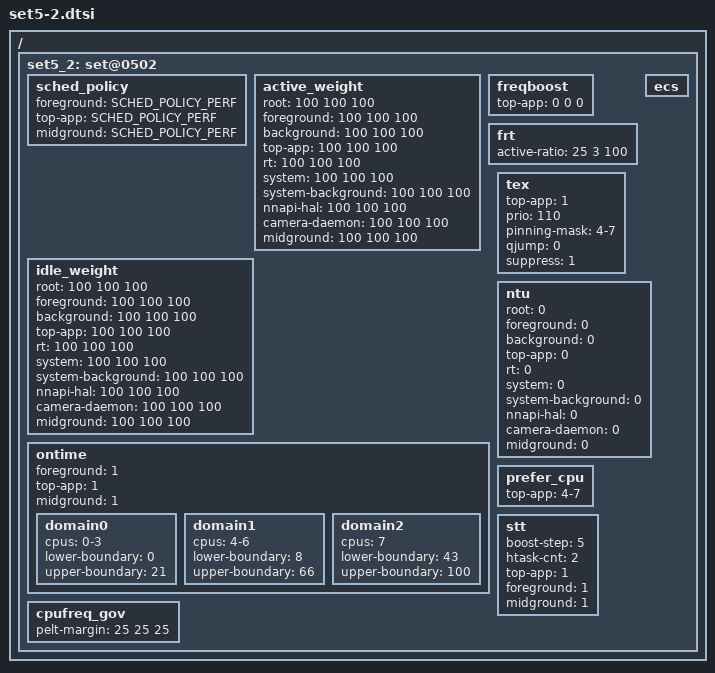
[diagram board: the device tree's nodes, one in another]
/ {
	/* camera mode - app boost */
	set5_2: set@0502 {
		/* schedudling policy */
		sched_policy {
			foreground 		= <SCHED_POLICY_PERF>;
			top-app			= <SCHED_POLICY_PERF>;
			midground = <SCHED_POLICY_PERF>;
		};

		/* weight (%) applied to active cpu's efficiency */
		active_weight {			/* LIT MED BIG */
			root            	= <100 100 100>;
			foreground      	= <100 100 100>;
			background      	= <100 100 100>;
			top-app         	= <100 100 100>;
			rt			= <100 100 100>;
			system			= <100 100 100>;
			system-background	= <100 100 100>;
			nnapi-hal		= < 100 100 100>;
			camera-daemon		= <100 100 100>;
			midground = <100 100 100>;
		};

		/* weight (%) applied to idle cpu's efficiency */
		idle_weight {	   		/* LIT  MED  BIG */
			root            	= <100 100 100>;
			foreground      	= <100 100 100>;
			background      	= <100 100 100>;
			top-app         	= <100 100 100>;
			rt			= <100 100 100>;
			system			= <100 100 100>;
			system-background	= <100 100 100>;
			nnapi-hal		= <100 100 100>;
			camera-daemon		= <100 100 100>;
			midground = <100 100 100>;
		};

		freqboost {
			top-app = <0 0 0>;
		};

		frt {	   			/* LIT MED BIG */
			active-ratio 		= < 25   3   100>;
		};

		/* Ontime Migration */
		ontime {
			foreground 	= <1>;
			top-app		= <1>;
			midground   = <1>;

			domain0 {
				cpus = "0-3";
				lower-boundary = <0>;
				upper-boundary = <21>;
			};
			domain1 {
				cpus = "4-6";
				lower-boundary = <8>;
				upper-boundary = <66>;
			};
			domain2 {
				cpus = "7";
				lower-boundary = <43>;
				upper-boundary = <100>;
			};
		};

		ecs { };

		tex {
			top-app		= <1>;
			prio		= <110>;

			pinning-mask	= "4-7";
			qjump		= <0>;
			suppress = <1>;
		};

		ntu {
			root = <0>;
			foreground = <0>;
			background = <0>;
			top-app = <0>;
			rt = <0>;
			system = <0>;
			system-background = <0>;
			nnapi-hal = <0>;
			camera-daemon = <0>;
			midground = <0>;
		};

		prefer_cpu {
			top-app = "4-7";
		};

		stt {
			boost-step = <5>;
			htask-cnt = <2>;
			top-app = <1>;
			foreground = <1>;
			midground = <1>;
		};

		cpufreq_gov {
			pelt-margin = <25 25 25>;
		};
	};
};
